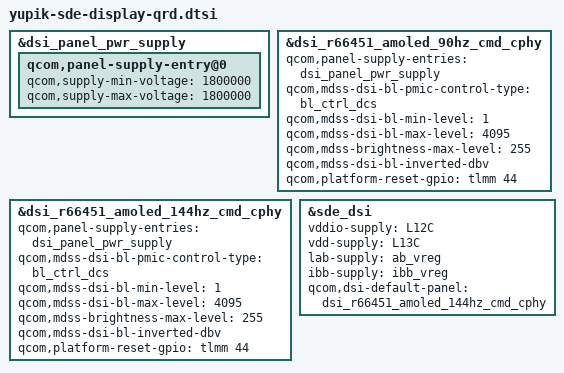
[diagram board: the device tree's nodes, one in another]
#include "yupik-sde-display.dtsi"

&dsi_panel_pwr_supply {
	qcom,panel-supply-entry@0 {
		qcom,supply-min-voltage = <1800000>;
		qcom,supply-max-voltage = <1800000>;
	};
};

&dsi_r66451_amoled_90hz_cmd_cphy {
	qcom,panel-supply-entries = <&dsi_panel_pwr_supply>;
	qcom,mdss-dsi-bl-pmic-control-type = "bl_ctrl_dcs";
	qcom,mdss-dsi-bl-min-level = <1>;
	qcom,mdss-dsi-bl-max-level = <4095>;
	qcom,mdss-brightness-max-level = <255>;
	qcom,mdss-dsi-bl-inverted-dbv;
	qcom,platform-reset-gpio = <&tlmm 44 0>;
};

&dsi_r66451_amoled_144hz_cmd_cphy {
	qcom,panel-supply-entries = <&dsi_panel_pwr_supply>;
	qcom,mdss-dsi-bl-pmic-control-type = "bl_ctrl_dcs";
	qcom,mdss-dsi-bl-min-level = <1>;
	qcom,mdss-dsi-bl-max-level = <4095>;
	qcom,mdss-brightness-max-level = <255>;
	qcom,mdss-dsi-bl-inverted-dbv;
	qcom,platform-reset-gpio = <&tlmm 44 0>;
};

&sde_dsi {
	vddio-supply = <&L12C>;
	vdd-supply = <&L13C>;
	lab-supply = <&ab_vreg>;
	ibb-supply = <&ibb_vreg>;
	qcom,dsi-default-panel = <&dsi_r66451_amoled_144hz_cmd_cphy >;
};
